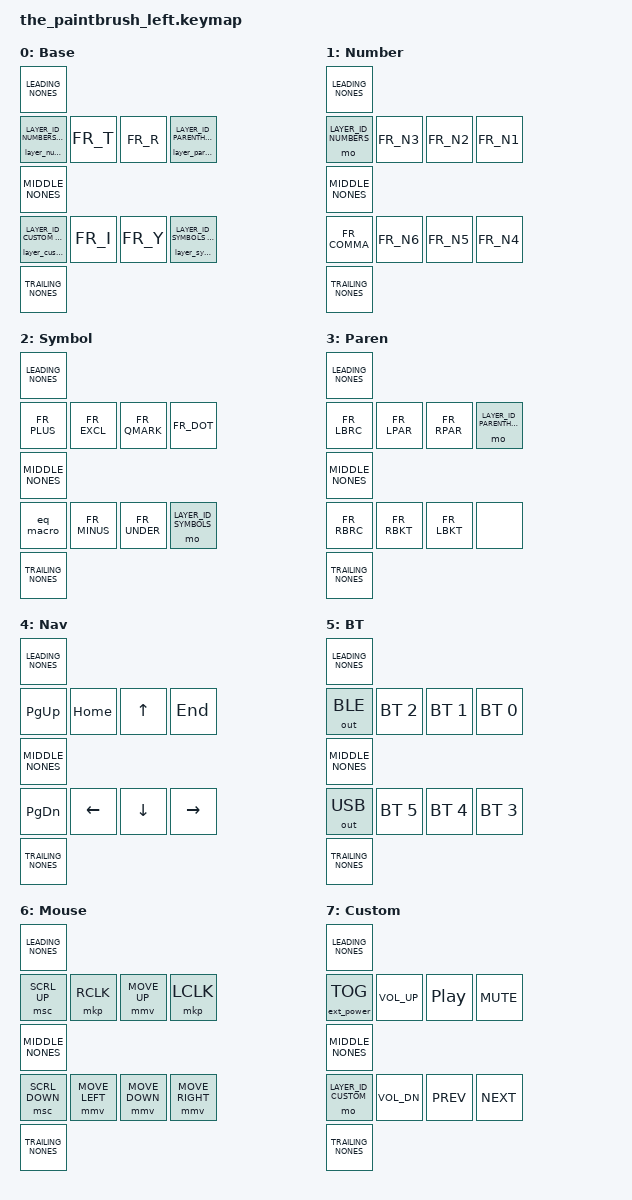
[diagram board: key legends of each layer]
/*
 * Copyright (c) 2021 Mike "KemoNine" Crosson
 * SPDX-License-Identifier: MIT
 *
 * Belgian French keymap for the Paintbrush Left
 * Uses keys_fr_belgian.h — all keycodes use FR_ prefix
 *
 * Physical layout (left hand, left to right):
 *   Top row:    S(0)  T(1)  R(2)  A(3)
 *   Bottom row: O(4)  I(5)  Y(6)  E(7)
 *
 * Hold keys:
 *   Hold S → Numbers layer
 *   Hold A → Parentheticals layer
 *   Hold E → Symbols layer
 *   Hold O → Custom layer
 */

#include <behaviors.dtsi>
#include <dt-bindings/zmk/keys.h>
#include <dt-bindings/zmk/bt.h>
#include <dt-bindings/zmk/outputs.h>
#include <dt-bindings/zmk/pointing.h>
#include <dt-bindings/zmk/ext_power.h>
#include "keys_fr_belgian.h"

#define ARDUX_LEFT 1

#define KEY_S 0
#define KEY_T 1
#define KEY_R 2
#define KEY_A 3
#define KEY_O 4
#define KEY_I 5
#define KEY_Y 6
#define KEY_E 7

#define LEADING_NONES  NONE(0,0,0)
#define MIDDLE_NONES   NONE(0,0,0)
#define TRAILING_NONES NONE(0,0,0)

#define LAYER_ID_BASE           0
#define LAYER_ID_NUMBERS        1
#define LAYER_ID_SYMBOLS        2
#define LAYER_ID_PARENTHETICALS 3
#define LAYER_ID_NAVIGATION     4
#define LAYER_ID_BT_SEL         5
#define LAYER_ID_MOUSE          6
#define LAYER_ID_CUSTOM         7

#include "ardux.dtsi"

/ {
    keymap {
        compatible = "zmk,keymap";

        base {
            display-name = "Base";
            bindings = <
                LEADING_NONES
                &layer_numbers_kp LAYER_ID_NUMBERS FR_S  &kp FR_T  &kp FR_R  &layer_parentheticals_kp LAYER_ID_PARENTHETICALS FR_A
                MIDDLE_NONES
                &layer_custom_kp LAYER_ID_CUSTOM FR_O    &kp FR_I  &kp FR_Y  &layer_symbols_kp LAYER_ID_SYMBOLS FR_E
                TRAILING_NONES
            >;
        };

        numbers {
            display-name = "Number";
            /*
             * Top row (left to right): hold  3  2  1
             * Bottom row:              ,     6  5  4
             * Combos: 7=AR  8=RT  9=EY  0=YI
             */
            bindings = <
                LEADING_NONES
                &mo LAYER_ID_NUMBERS  &kp FR_N3  &kp FR_N2  &kp FR_N1
                MIDDLE_NONES
                &kp FR_COMMA          &kp FR_N6  &kp FR_N5  &kp FR_N4
                TRAILING_NONES
            >;
        };

        symbols {
            display-name = "Symbol";
            /*
             * Hold E (bottom right), then press:
             *   S → +    T → !    R → ?    A → .
             *   O → =    I → -    Y → _    E → (hold)
             */
            bindings = <
                LEADING_NONES
                &kp FR_PLUS   &kp FR_EXCL  &kp FR_QMARK  &kp FR_DOT
                MIDDLE_NONES
                &eq_macro     &kp FR_MINUS &kp FR_UNDER  &mo LAYER_ID_SYMBOLS
                TRAILING_NONES
            >;
        };

        parentheticals {
            display-name = "Paren";
            /*
             * Hold A (top right), then press:
             *   S → {    T → (    R → )    A → (hold)
             *   O → }    I → ]    Y → [    E → none
             */
            bindings = <
                LEADING_NONES
                &kp FR_LBRC  &kp FR_LPAR  &kp FR_RPAR  &mo LAYER_ID_PARENTHETICALS
                MIDDLE_NONES
                &kp FR_RBRC  &kp FR_RBKT  &kp FR_LBKT  &none
                TRAILING_NONES
            >;
        };

        navigation {
            display-name = "Nav";
            /*
             * Top row:    PgUp  Home  Up    End
             * Bottom row: PgDn  Left  Down  Right
             */
            bindings = <
                LEADING_NONES
                &kp PG_UP  &kp HOME  &kp UP    &kp END
                MIDDLE_NONES
                &kp PG_DN  &kp LEFT  &kp DOWN  &kp RIGHT
                TRAILING_NONES
            >;
        };

        bt {
            display-name = "BT";
            /*
             * Top row:    BLE   BT2   BT1   BT0
             * Bottom row: USB   BT5   BT4   BT3
             */
            bindings = <
                LEADING_NONES
                &out OUT_BLE  &bt BT_SEL 2  &bt BT_SEL 1  &bt BT_SEL 0
                MIDDLE_NONES
                &out OUT_USB  &bt BT_SEL 5  &bt BT_SEL 4  &bt BT_SEL 3
                TRAILING_NONES
            >;
        };

        mouse {
            display-name = "Mouse";
            /*
             * Top row:    Scroll Up   Right click  Mouse Up    Left click
             * Bottom row: Scroll Down Mouse Left   Mouse Down  Mouse Right
             */
            bindings = <
                LEADING_NONES
                &msc SCRL_UP    &mkp RCLK      &mmv MOVE_UP    &mkp LCLK
                MIDDLE_NONES
                &msc SCRL_DOWN  &mmv MOVE_LEFT &mmv MOVE_DOWN  &mmv MOVE_RIGHT
                TRAILING_NONES
            >;
        };

        custom {
            display-name = "Custom";
            /*
             * Hold O (bottom left), then press:
             *   S → EP_TOG  ← toggles OLED power (test key — remove once screen works)
             *   T → Volume Up
             *   R → Play/Pause
             *   A → Mute
             *   O → (hold)
             *   I → Volume Down
             *   Y → Previous track
             *   E → Next track
             */
            bindings = <
                LEADING_NONES
                &ext_power EP_TOG  &kp C_VOL_UP  &kp C_PP   &kp C_MUTE
                MIDDLE_NONES
                &mo LAYER_ID_CUSTOM &kp C_VOL_DN  &kp C_PREV &kp C_NEXT
                TRAILING_NONES
            >;
        };
    };
};
